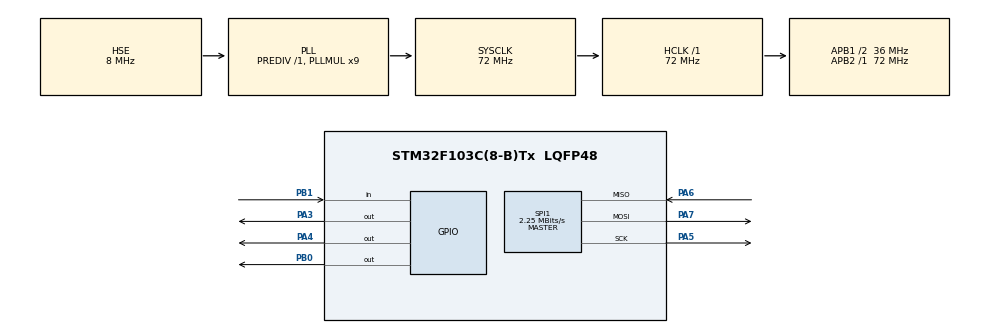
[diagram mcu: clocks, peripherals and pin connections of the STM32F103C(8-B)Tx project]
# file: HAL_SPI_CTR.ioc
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Mcu.Family=STM32F1
Mcu.Name=STM32F103C(8-B)Tx
Mcu.Package=LQFP48
NVIC.PriorityGroup=NVIC_PRIORITYGROUP_4
NVIC.SPI1_IRQn=true\:0\:0\:false\:false\:true\:true\:true\:true
NVIC.TIM2_IRQn=true\:0\:0\:false\:false\:true\:true\:true\:true
PA13.Mode=Serial_Wire
PA13.Signal=SYS_JTMS-SWDIO
PA14.Mode=Serial_Wire
PA14.Signal=SYS_JTCK-SWCLK
PA3.Signal=GPIO_Output
PA4.Signal=GPIO_Output
PA5.Mode=Full_Duplex_Master
PA5.Signal=SPI1_SCK
PA6.Mode=Full_Duplex_Master
PA6.Signal=SPI1_MISO
PA7.Mode=Full_Duplex_Master
PA7.Signal=SPI1_MOSI
PB0.Signal=GPIO_Output
PB1.GPIO_PuPd=GPIO_PULLUP
PB1.Signal=GPIO_Input
PD0-OSC_IN.Mode=HSE-External-Oscillator
PD0-OSC_IN.Signal=RCC_OSC_IN
PD1-OSC_OUT.Mode=HSE-External-Oscillator
PD1-OSC_OUT.Signal=RCC_OSC_OUT
ProjectManager.HeapSize=0x200
ProjectManager.StackSize=0x400
ProjectManager.TargetToolchain=MDK-ARM V5.32
RCC.AHBFreq_Value=72000000
RCC.APB1CLKDivider=RCC_HCLK_DIV2
RCC.APB1Freq_Value=36000000
RCC.APB1TimFreq_Value=72000000
RCC.APB2Freq_Value=72000000
RCC.APB2TimFreq_Value=72000000
RCC.HCLKFreq_Value=72000000
RCC.PLLMUL=RCC_PLL_MUL9
RCC.PLLSourceVirtual=RCC_PLLSOURCE_HSE
RCC.SYSCLKFreq_VALUE=72000000
RCC.SYSCLKSource=RCC_SYSCLKSOURCE_PLLCLK
RCC.USBFreq_Value=72000000
SPI1.BaudRatePrescaler=SPI_BAUDRATEPRESCALER_32
SPI1.CRCCalculation=SPI_CRCCALCULATION_DISABLE
SPI1.CalculateBaudRate=2.25 MBits/s
SPI1.Direction=SPI_DIRECTION_2LINES
SPI1.Mode=SPI_MODE_MASTER
SPI1.VirtualType=VM_MASTER
TIM2.Period=1000-1
TIM2.Prescaler=72-1
VP_TIM2_VS_ClockSourceINT.Mode=Internal
board=custom

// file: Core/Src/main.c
/* USER CODE BEGIN Header */
/**
  ******************************************************************************
  * @file           : main.c
  * @brief          : Main program body
  ******************************************************************************
  * @attention
  *
  * Copyright (c) 2023 STMicroelectronics.
  * All rights reserved.
  *
  * This software is licensed under terms that can be found in the LICENSE file
  * in the root directory of this software component.
  * If no LICENSE file comes with this software, it is provided AS-IS.
  *
  ******************************************************************************
  */
/* USER CODE END Header */
#include "main.h"
#include "spi.h"
#include "tim.h"
#include "gpio.h"

/* USER CODE BEGIN Includes */
#include "drv_RF24L01.h"
#include "drv_spi.h"
/* USER CODE END Includes */

void SystemClock_Config(void);

/* USER CODE BEGIN 0 */
uint8_t a = 0;
uint8_t b = 0;
/* USER CODE END 0 */

int main(void)
{

  /* MCU Configuration--------------------------------------------------------*/

  /* Reset of all peripherals, Initializes the Flash interface and the Systick. */
  HAL_Init();

  /* Configure the system clock */
  SystemClock_Config();

  /* Initialize all configured peripherals */
  MX_GPIO_Init();
  MX_SPI1_Init();
  MX_TIM2_Init();
  /* USER CODE BEGIN 2 */
      for(uint8_t i=0;i<32;i++)
  {
    NRF24L01_bus.RxPacket.Rxbuffer[i] = 0;
  }
  NRF24L01_bus.RxPacket.Rxlength = 32;

  RF24L01_Port_Init();
  // HAL_GPIO_WritePin(GPIOA,GPIO_PIN_3,GPIO_PIN_RESET);
  // NRF24L01_Read_Status_Register(&NRF24L01_rtx);
  RF24L01_Init(&NRF24L01_rtx);
  //NRF24L01_Set_Speed(&NRF24L01_rtx,SPEED_1M);
  //NRF24L01_Set_Power(&NRF24L01_rtx, PWR_12DB);
  RF24L01_Set_Mode(&NRF24L01_rtx, MODE_RX);

  /* USER CODE END 2 */

  /* Infinite loop */
  while (1)
  {

    /* USER CODE BEGIN 3 */
	  NRF24L01_check(&NRF24L01_rtx);
    NRF24L01_RxPacket(&NRF24L01_rtx, &NRF24L01_bus);
    a = NRF24L01_Read_Reg(&NRF24L01_rtx, STATUS);
    b = NRF24L01_Read_Reg(&NRF24L01_rtx, NRF_FIFO_STATUS);

  }
  /* USER CODE END 3 */
}

void SystemClock_Config(void)
{
  RCC_OscInitTypeDef RCC_OscInitStruct = {0};
  RCC_ClkInitTypeDef RCC_ClkInitStruct = {0};

  /** Initializes the RCC Oscillators according to the specified parameters
  * in the RCC_OscInitTypeDef structure.
  */
  RCC_OscInitStruct.OscillatorType = RCC_OSCILLATORTYPE_HSE;
  RCC_OscInitStruct.HSEState = RCC_HSE_ON;
  RCC_OscInitStruct.HSEPredivValue = RCC_HSE_PREDIV_DIV1;
  RCC_OscInitStruct.HSIState = RCC_HSI_ON;
  RCC_OscInitStruct.PLL.PLLState = RCC_PLL_ON;
  RCC_OscInitStruct.PLL.PLLSource = RCC_PLLSOURCE_HSE;
  RCC_OscInitStruct.PLL.PLLMUL = RCC_PLL_MUL9;
  if (HAL_RCC_OscConfig(&RCC_OscInitStruct) != HAL_OK)
  {
    Error_Handler();
  }

  /** Initializes the CPU, AHB and APB buses clocks
  */
  RCC_ClkInitStruct.ClockType = RCC_CLOCKTYPE_HCLK|RCC_CLOCKTYPE_SYSCLK
                              |RCC_CLOCKTYPE_PCLK1|RCC_CLOCKTYPE_PCLK2;
  RCC_ClkInitStruct.SYSCLKSource = RCC_SYSCLKSOURCE_PLLCLK;
  RCC_ClkInitStruct.AHBCLKDivider = RCC_SYSCLK_DIV1;
  RCC_ClkInitStruct.APB1CLKDivider = RCC_HCLK_DIV2;
  RCC_ClkInitStruct.APB2CLKDivider = RCC_HCLK_DIV1;

  if (HAL_RCC_ClockConfig(&RCC_ClkInitStruct, FLASH_LATENCY_2) != HAL_OK)
  {
    Error_Handler();
  }
}

void Error_Handler(void)
{
  __disable_irq();
  while (1)
  {
  }
}
